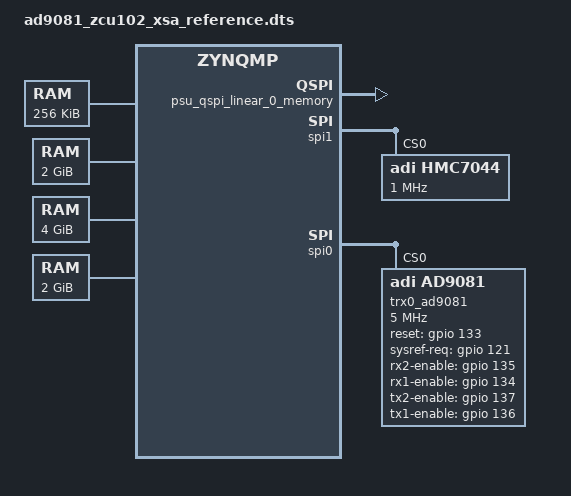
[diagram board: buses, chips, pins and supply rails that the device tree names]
/*
 * ADI Device Tree (merged) — ad9081_zcu102
 *
 * Generated by pyadi-dt from XSA. Do not edit manually — re-run
 * the pipeline to regenerate from the XSA source.
 *
 * Compile with:
 *   dtc -I dts -O dtb -o system.dtb ad9081_zcu102.dts
 */
/dts-v1/;
#include "zynqmp.dtsi"
#include "zynqmp-u-boot.dtsi"
#include "zynqmp-clk-ccf.dtsi"
#include "pl.dtsi"
#include "pcw.dtsi"
/ {
	board = "zcu102";
	compatible = "xlnx,zcu102";
	device_id = "xczu9eg";
	slrcount = <1>;
	family = "ZynqMP";
	speed_grade = "2";
	psu_ocm_ram_0_memory: memory@FFFC0000 {
		compatible = "xlnx,psu-ocm-ram-0-1.0" , "mmio-sram";
		xlnx,ip-name = "psu_ocm_ram_0";
		memory_type = "memory";
		reg = <0x0 0xFFFC0000 0x0 0x40000>;
	};
	psu_r5_ddr_0_memory: memory@100000 {
		compatible = "xlnx,psu-ddr-1.0";
		xlnx,ip-name = "psu_ddr";
		device_type = "memory";
		memory_type = "memory";
		reg = <0x100000 0x7FEFFFFF>;
	};
	psu_ddr_0_memory: memory@0 {
		compatible = "xlnx,psu-ddr-1.0";
		xlnx,ip-name = "psu_ddr";
		device_type = "memory";
		memory_type = "memory";
		reg = <0x0 0x7FF00000>, <0x0 0x7FF00000 0x0 0x100000>;
	};
	psu_ddr_1_memory: memory@800000000 {
		compatible = "xlnx,psu-ddr-1.0";
		xlnx,ip-name = "psu_ddr";
		device_type = "memory";
		memory_type = "memory";
		reg = <0x00000008 0x00000000 0x0 0x80000000>;
	};
	psu_qspi_linear_0_memory: memory@c0000000 {
		compatible = "xlnx,psu-qspi-linear-1.0-memory";
		xlnx,ip-name = "psu_qspi_linear";
		memory_type = "linear_flash";
		reg = <0x0 0xc0000000 0x0 0x20000000>;
	};
	chosen {
		bootargs = "earlycon console=ttyPS0,115200 clk_ignore_unused init_fatal_sh=1";
		stdout-path = "serial0:115200n8";
	};
	aliases {
		serial0 = &uart0;
		spi0 = &qspi;
		serial1 = &uart1;
		serial2 = &coresight_0;
		i2c0 = &i2c1;
		i2c1 = &i2c0;
		ethernet0 = &gem3;
	};
	cpus_a53: cpus {
		compatible = "cpus,cluster";
		address-map = <0x0 0xf0000000 &amba 0x0 0xf0000000 0x0 0x10000000>, 
			      <0x0 0xf9000000 &amba_apu 0x0 0xf9000000 0x0 0x80000>, 
			      <0x0 0x0 &zynqmp_reset 0x0 0x0 0x0 0x0>, 
			      <0x0 0x0 &pinctrl0 0x0 0x0 0x0 0x0>, 
			      <0x0 0xffa50800 &ams_ps 0x0 0xffa50800 0x0 0x400>, 
			      <0x0 0xffa50c00 &ams_pl 0x0 0xffa50c00 0x0 0x400>, 
			      <0x0 0xFFFC0000 &psu_ocm_ram_0_memory 0x0 0xFFFC0000 0x0 0x40000>, 
			      <0x0 0xff300000 &ipi0 0x0 0xff300000 0x0 0x10000>, 
			      <0x0 0x0 &psu_ddr_0_memory 0x0 0x0 0x0 0x7FF00000>, 
			      <0x00000008 0x00000000 &psu_ddr_1_memory 0x00000008 0x00000000 0x0 0x80000000>, 
			      <0x0 0x84a10000 &rx_mxfe_tpl_core_adc_tpl_core 0x0 0x84a10000 0x0 0x2000>, 
			      <0x0 0x84a60000 &axi_mxfe_rx_xcvr 0x0 0x84a60000 0x0 0x10000>, 
			      <0x0 0x84a90000 &axi_mxfe_rx_jesd_rx_axi 0x0 0x84a90000 0x0 0x4000>, 
			      <0x0 0x84b10000 &tx_mxfe_tpl_core_dac_tpl_core 0x0 0x84b10000 0x0 0x2000>, 
			      <0x0 0x84b60000 &axi_mxfe_tx_xcvr 0x0 0x84b60000 0x0 0x10000>, 
			      <0x0 0x84b90000 &axi_mxfe_tx_jesd_tx_axi 0x0 0x84b90000 0x0 0x4000>, 
			      <0x0 0x85000000 &axi_sysid_0 0x0 0x85000000 0x0 0x10000>, 
			      <0x0 0x9c420000 &axi_mxfe_rx_dma 0x0 0x9c420000 0x0 0x1000>, 
			      <0x0 0x9c430000 &axi_mxfe_tx_dma 0x0 0x9c430000 0x0 0x1000>, 
			      <0x0 0x9c440000 &mxfe_tx_data_offload_i_data_offload 0x0 0x9c440000 0x0 0x10000>, 
			      <0x0 0x9c450000 &mxfe_rx_data_offload_i_data_offload 0x0 0x9c450000 0x0 0x10000>, 
			      <0x0 0xf9010000 &gic_a53 0x0 0xf9010000 0x0 0x70000>, 
			      <0x0 0xffa80000 &lpd_dma_chan1 0x0 0xffa80000 0x0 0x10000>, 
			      <0x0 0xffa90000 &lpd_dma_chan2 0x0 0xffa90000 0x0 0x10000>, 
			      <0x0 0xffaa0000 &lpd_dma_chan3 0x0 0xffaa0000 0x0 0x10000>, 
			      <0x0 0xffab0000 &lpd_dma_chan4 0x0 0xffab0000 0x0 0x10000>, 
			      <0x0 0xffac0000 &lpd_dma_chan5 0x0 0xffac0000 0x0 0x10000>, 
			      <0x0 0xffad0000 &lpd_dma_chan6 0x0 0xffad0000 0x0 0x10000>, 
			      <0x0 0xffae0000 &lpd_dma_chan7 0x0 0xffae0000 0x0 0x10000>, 
			      <0x0 0xffaf0000 &lpd_dma_chan8 0x0 0xffaf0000 0x0 0x10000>, 
			      <0x0 0xfd360000 &psu_afi_0 0x0 0xfd360000 0x0 0x10000>, 
			      <0x0 0xfd370000 &psu_afi_1 0x0 0xfd370000 0x0 0x10000>, 
			      <0x0 0xfd380000 &psu_afi_2 0x0 0xfd380000 0x0 0x10000>, 
			      <0x0 0xfd390000 &psu_afi_3 0x0 0xfd390000 0x0 0x10000>, 
			      <0x0 0xfd3a0000 &psu_afi_4 0x0 0xfd3a0000 0x0 0x10000>, 
			      <0x0 0xfd3b0000 &psu_afi_5 0x0 0xfd3b0000 0x0 0x10000>, 
			      <0x0 0xff9b0000 &psu_afi_6 0x0 0xff9b0000 0x0 0x10000>, 
			      <0x0 0xffa50000 &xilinx_ams 0x0 0xffa50000 0x0 0x10000>, 
			      <0x0 0xfd0b0000 &perf_monitor_ddr 0x0 0xfd0b0000 0x0 0x10000>, 
			      <0x0 0xffa00000 &perf_monitor_ocm 0x0 0xffa00000 0x0 0x10000>, 
			      <0x0 0xffa10000 &perf_monitor_lpd 0x0 0xffa10000 0x0 0x10000>, 
			      <0x0 0xfd490000 &perf_monitor_cci 0x0 0xfd490000 0x0 0x10000>, 
			      <0x0 0xfd5c0000 &psu_apu 0x0 0xfd5c0000 0x0 0x10000>, 
			      <0x0 0xff070000 &can1 0x0 0xff070000 0x0 0x10000>, 
			      <0x0 0xfd6e0000 &psu_cci_gpv 0x0 0xfd6e0000 0x0 0x10000>, 
			      <0x0 0xfd5e0000 &psu_cci_reg 0x0 0xfd5e0000 0x0 0x10000>, 
			      <0x0 0xfe800000 &coresight_0 0x0 0xfe800000 0x0 0x800000>, 
			      <0x0 0xfd1a0000 &psu_crf_apb 0x0 0xfd1a0000 0x0 0x140000>, 
			      <0x0 0xff5e0000 &psu_crl_apb 0x0 0xff5e0000 0x0 0x280000>, 
			      <0x0 0xffca0000 &psu_csu_0 0x0 0xffca0000 0x0 0x10000>, 
			      <0x0 0xffc80000 &csudma_0 0x0 0xffc80000 0x0 0x20000>, 
			      <0x0 0xff380000 &psu_ctrl_ipi 0x0 0xff380000 0x0 0x80000>, 
			      <0x0 0xfd080000 &psu_ddr_phy 0x0 0xfd080000 0x0 0x10000>, 
			      <0x0 0xfd090000 &psu_ddr_qos_ctrl 0x0 0xfd090000 0x0 0x10000>, 
			      <0x0 0xfd000000 &psu_ddr_xmpu0_cfg 0x0 0xfd000000 0x0 0x10000>, 
			      <0x0 0xfd010000 &psu_ddr_xmpu1_cfg 0x0 0xfd010000 0x0 0x10000>, 
			      <0x0 0xfd020000 &psu_ddr_xmpu2_cfg 0x0 0xfd020000 0x0 0x10000>, 
			      <0x0 0xfd030000 &psu_ddr_xmpu3_cfg 0x0 0xfd030000 0x0 0x10000>, 
			      <0x0 0xfd040000 &psu_ddr_xmpu4_cfg 0x0 0xfd040000 0x0 0x10000>, 
			      <0x0 0xfd050000 &psu_ddr_xmpu5_cfg 0x0 0xfd050000 0x0 0x10000>, 
			      <0x0 0xfd070000 &mc 0x0 0xfd070000 0x0 0x1000>, 
			      <0x0 0xfd4a0000 &zynqmp_dpsub 0x0 0xfd4a0000 0x0 0x10000>, 
			      <0x0 0xfd4c0000 &zynqmp_dpdma 0x0 0xfd4c0000 0x0 0x10000>, 
			      <0x0 0xffcc0000 &psu_efuse 0x0 0xffcc0000 0x0 0x10000>, 
			      <0x0 0xff0e0000 &gem3 0x0 0xff0e0000 0x0 0x10000>, 
			      <0x0 0xfd700000 &psu_fpd_gpv 0x0 0xfd700000 0x0 0x100000>, 
			      <0x0 0xfd610000 &psu_fpd_slcr 0x0 0xfd610000 0x0 0x80000>, 
			      <0x0 0xfd690000 &psu_fpd_slcr_secure 0x0 0xfd690000 0x0 0x40000>, 
			      <0x0 0xfd5d0000 &psu_fpd_xmpu_cfg 0x0 0xfd5d0000 0x0 0x10000>, 
			      <0x0 0xfd4f0000 &psu_fpd_xmpu_sink 0x0 0xfd4f0000 0x0 0x10000>, 
			      <0x0 0xfd500000 &fpd_dma_chan1 0x0 0xfd500000 0x0 0x10000>, 
			      <0x0 0xfd510000 &fpd_dma_chan2 0x0 0xfd510000 0x0 0x10000>, 
			      <0x0 0xfd520000 &fpd_dma_chan3 0x0 0xfd520000 0x0 0x10000>, 
			      <0x0 0xfd530000 &fpd_dma_chan4 0x0 0xfd530000 0x0 0x10000>, 
			      <0x0 0xfd540000 &fpd_dma_chan5 0x0 0xfd540000 0x0 0x10000>, 
			      <0x0 0xfd550000 &fpd_dma_chan6 0x0 0xfd550000 0x0 0x10000>, 
			      <0x0 0xfd560000 &fpd_dma_chan7 0x0 0xfd560000 0x0 0x10000>, 
			      <0x0 0xfd570000 &fpd_dma_chan8 0x0 0xfd570000 0x0 0x10000>, 
			      <0x0 0xff0a0000 &gpio 0x0 0xff0a0000 0x0 0x10000>, 
			      <0x0 0xfd4b0000 &gpu 0x0 0xfd4b0000 0x0 0x10000>, 
			      <0x0 0xff020000 &i2c0 0x0 0xff020000 0x0 0x10000>, 
			      <0x0 0xff030000 &i2c1 0x0 0xff030000 0x0 0x10000>, 
			      <0x0 0xff250000 &psu_iou_scntr 0x0 0xff250000 0x0 0x10000>, 
			      <0x0 0xff260000 &psu_iou_scntrs 0x0 0xff260000 0x0 0x10000>, 
			      <0x0 0xff240000 &psu_iousecure_slcr 0x0 0xff240000 0x0 0x10000>, 
			      <0x0 0xff180000 &psu_iouslcr_0 0x0 0xff180000 0x0 0xc0000>, 
			      <0x0 0xff410000 &psu_lpd_slcr 0x0 0xff410000 0x0 0xa0000>, 
			      <0x0 0xff4b0000 &psu_lpd_slcr_secure 0x0 0xff4b0000 0x0 0x30000>, 
			      <0x0 0xff980000 &lpd_xppu 0x0 0xff980000 0x0 0x10000>, 
			      <0x0 0xff9c0000 &psu_lpd_xppu_sink 0x0 0xff9c0000 0x0 0x10000>, 
			      <0x0 0xffcf0000 &psu_mbistjtag 0x0 0xffcf0000 0x0 0x10000>, 
			      <0x0 0xff990000 &psu_message_buffers 0x0 0xff990000 0x0 0x10000>, 
			      <0x0 0xff960000 &ocm 0x0 0xff960000 0x0 0x10000>, 
			      <0x0 0xffa70000 &psu_ocm_xmpu_cfg 0x0 0xffa70000 0x0 0x10000>, 
			      <0x0 0xfd0e0000 &pcie 0x0 0xfd0e0000 0x0 0x10000>, 
			      <0x0 0xfd480000 &psu_pcie_attrib_0 0x0 0xfd480000 0x0 0x10000>, 
			      <0x0 0xfd0f0000 &psu_pcie_dma 0x0 0xfd0f0000 0x0 0x10000>, 
			      <0x00000006 0x00000000 &psu_pcie_high1 0x00000006 0x00000000 0x00000002 0x00000000>, 
			      <0x00000080 0x00000000 &psu_pcie_high2 0x00000080 0x00000000 0x00000040 0x00000000>, 
			      <0x0 0xe0000000 &psu_pcie_low 0x0 0xe0000000 0x0 0x10000000>, 
			      <0x0 0xffd80000 &psu_pmu_global_0 0x0 0xffd80000 0x0 0x40000>, 
			      <0x0 0xff0f0000 &qspi 0x0 0xff0f0000 0x0 0x10000>, 
			      <0x0 0xc0000000 &psu_qspi_linear_0_memory 0x0 0xc0000000 0x0 0x20000000>, 
			      <0x0 0xffe00000 &psu_r5_0_atcm_global 0x0 0xffe00000 0x0 0x10000>, 
			      <0x0 0xffe20000 &psu_r5_0_btcm_global 0x0 0xffe20000 0x0 0x10000>, 
			      <0x0 0xffe90000 &psu_r5_1_atcm_global 0x0 0xffe90000 0x0 0x10000>, 
			      <0x0 0xffeb0000 &psu_r5_1_btcm_global 0x0 0xffeb0000 0x0 0x10000>, 
			      <0x0 0xffe00000 &psu_r5_tcm_ram_global 0x0 0xffe00000 0x0 0x40000>, 
			      <0x0 0xff9a0000 &psu_rpu 0x0 0xff9a0000 0x0 0x10000>, 
			      <0x0 0xffce0000 &psu_rsa 0x0 0xffce0000 0x0 0x10000>, 
			      <0x0 0xffa60000 &rtc 0x0 0xffa60000 0x0 0x10000>, 
			      <0x0 0xfd0c0000 &sata 0x0 0xfd0c0000 0x0 0x10000>, 
			      <0x0 0xff170000 &sdhci1 0x0 0xff170000 0x0 0x10000>, 
			      <0x0 0xfd400000 &psgtr 0x0 0xfd400000 0x0 0x80000>, 
			      <0x0 0xfd3d0000 &psu_siou 0x0 0xfd3d0000 0x0 0x10000>, 
			      <0x0 0xfd800000 &smmu 0x0 0xfd800000 0x0 0x800000>, 
			      <0x0 0xfd5f0000 &psu_smmu_reg 0x0 0xfd5f0000 0x0 0x10000>, 
			      <0x0 0xff040000 &spi0 0x0 0xff040000 0x0 0x10000>, 
			      <0x0 0xff050000 &spi1 0x0 0xff050000 0x0 0x10000>, 
			      <0x0 0xff110000 &ttc0 0x0 0xff110000 0x0 0x10000>, 
			      <0x0 0xff120000 &ttc1 0x0 0xff120000 0x0 0x10000>, 
			      <0x0 0xff130000 &ttc2 0x0 0xff130000 0x0 0x10000>, 
			      <0x0 0xff140000 &ttc3 0x0 0xff140000 0x0 0x10000>, 
			      <0x0 0xff000000 &uart0 0x0 0xff000000 0x0 0x10000>, 
			      <0x0 0xff010000 &uart1 0x0 0xff010000 0x0 0x10000>, 
			      <0x0 0xff9d0000 &usb0 0x0 0xff9d0000 0x0 0x10000>, 
			      <0x0 0xfe200000 &dwc3_0 0x0 0xfe200000 0x0 0x100000>, 
			      <0x0 0xff150000 &lpd_watchdog 0x0 0xff150000 0x0 0x10000>, 
			      <0x0 0xfd4d0000 &watchdog0 0x0 0xfd4d0000 0x0 0x10000>;
		#ranges-address-cells = <0x2>;
		#ranges-size-cells = <0x2>;
	};
	cpus_r5_0: cpus-r5@0 {
		compatible = "cpus,cluster";
		address-map = <0xf0000000 &amba 0xf0000000 0x10000000>, 
			      <0xf9000000 &amba_rpu 0xf9000000 0x3000>, 
			      <0x0 &zynqmp_reset 0x0 0x0>, 
			      <0xFFFC0000 &psu_ocm_ram_0_memory 0xFFFC0000 0x40000>, 
			      <0xff310000 &ipi1 0xff310000 0x10000>, 
			      <0x100000 &psu_r5_ddr_0_memory 0x100000 0x7FEFFFFF>, 
			      <0x84a10000 &rx_mxfe_tpl_core_adc_tpl_core 0x84a10000 0x2000>, 
			      <0x84a60000 &axi_mxfe_rx_xcvr 0x84a60000 0x10000>, 
			      <0x84a90000 &axi_mxfe_rx_jesd_rx_axi 0x84a90000 0x4000>, 
			      <0x84b10000 &tx_mxfe_tpl_core_dac_tpl_core 0x84b10000 0x2000>, 
			      <0x84b60000 &axi_mxfe_tx_xcvr 0x84b60000 0x10000>, 
			      <0x84b90000 &axi_mxfe_tx_jesd_tx_axi 0x84b90000 0x4000>, 
			      <0x85000000 &axi_sysid_0 0x85000000 0x10000>, 
			      <0x9c420000 &axi_mxfe_rx_dma 0x9c420000 0x1000>, 
			      <0x9c430000 &axi_mxfe_tx_dma 0x9c430000 0x1000>, 
			      <0x9c440000 &mxfe_tx_data_offload_i_data_offload 0x9c440000 0x10000>, 
			      <0x9c450000 &mxfe_rx_data_offload_i_data_offload 0x9c450000 0x10000>, 
			      <0xffa80000 &lpd_dma_chan1 0xffa80000 0x10000>, 
			      <0xffa90000 &lpd_dma_chan2 0xffa90000 0x10000>, 
			      <0xffaa0000 &lpd_dma_chan3 0xffaa0000 0x10000>, 
			      <0xffab0000 &lpd_dma_chan4 0xffab0000 0x10000>, 
			      <0xffac0000 &lpd_dma_chan5 0xffac0000 0x10000>, 
			      <0xffad0000 &lpd_dma_chan6 0xffad0000 0x10000>, 
			      <0xffae0000 &lpd_dma_chan7 0xffae0000 0x10000>, 
			      <0xffaf0000 &lpd_dma_chan8 0xffaf0000 0x10000>, 
			      <0xfd360000 &psu_afi_0 0xfd360000 0x10000>, 
			      <0xfd370000 &psu_afi_1 0xfd370000 0x10000>, 
			      <0xfd380000 &psu_afi_2 0xfd380000 0x10000>, 
			      <0xfd390000 &psu_afi_3 0xfd390000 0x10000>, 
			      <0xfd3a0000 &psu_afi_4 0xfd3a0000 0x10000>, 
			      <0xfd3b0000 &psu_afi_5 0xfd3b0000 0x10000>, 
			      <0xff9b0000 &psu_afi_6 0xff9b0000 0x10000>, 
			      <0xffa50000 &xilinx_ams 0xffa50000 0x10000>, 
			      <0xfd0b0000 &perf_monitor_ddr 0xfd0b0000 0x10000>, 
			      <0xffa00000 &perf_monitor_ocm 0xffa00000 0x10000>, 
			      <0xffa10000 &perf_monitor_lpd 0xffa10000 0x10000>, 
			      <0xfd490000 &perf_monitor_cci 0xfd490000 0x10000>, 
			      <0xfd5c0000 &psu_apu 0xfd5c0000 0x10000>, 
			      <0xff070000 &can1 0xff070000 0x10000>, 
			      <0xfd6e0000 &psu_cci_gpv 0xfd6e0000 0x10000>, 
			      <0xfd5e0000 &psu_cci_reg 0xfd5e0000 0x10000>, 
			      <0xfe800000 &coresight_0 0xfe800000 0x800000>, 
			      <0xfd1a0000 &psu_crf_apb 0xfd1a0000 0x140000>, 
			      <0xff5e0000 &psu_crl_apb 0xff5e0000 0x280000>, 
			      <0xffca0000 &psu_csu_0 0xffca0000 0x10000>, 
			      <0xffc80000 &csudma_0 0xffc80000 0x20000>, 
			      <0xff380000 &psu_ctrl_ipi 0xff380000 0x80000>, 
			      <0xfd080000 &psu_ddr_phy 0xfd080000 0x10000>, 
			      <0xfd090000 &psu_ddr_qos_ctrl 0xfd090000 0x10000>, 
			      <0xfd000000 &psu_ddr_xmpu0_cfg 0xfd000000 0x10000>, 
			      <0xfd010000 &psu_ddr_xmpu1_cfg 0xfd010000 0x10000>, 
			      <0xfd020000 &psu_ddr_xmpu2_cfg 0xfd020000 0x10000>, 
			      <0xfd030000 &psu_ddr_xmpu3_cfg 0xfd030000 0x10000>, 
			      <0xfd040000 &psu_ddr_xmpu4_cfg 0xfd040000 0x10000>, 
			      <0xfd050000 &psu_ddr_xmpu5_cfg 0xfd050000 0x10000>, 
			      <0xfd070000 &mc 0xfd070000 0x1000>, 
			      <0xfd4a0000 &zynqmp_dpsub 0xfd4a0000 0x10000>, 
			      <0xfd4c0000 &zynqmp_dpdma 0xfd4c0000 0x10000>, 
			      <0xffcc0000 &psu_efuse 0xffcc0000 0x10000>, 
			      <0xff0e0000 &gem3 0xff0e0000 0x10000>, 
			      <0xfd700000 &psu_fpd_gpv 0xfd700000 0x100000>, 
			      <0xfd610000 &psu_fpd_slcr 0xfd610000 0x80000>, 
			      <0xfd690000 &psu_fpd_slcr_secure 0xfd690000 0x40000>, 
			      <0xfd5d0000 &psu_fpd_xmpu_cfg 0xfd5d0000 0x10000>, 
			      <0xfd4f0000 &psu_fpd_xmpu_sink 0xfd4f0000 0x10000>, 
			      <0xfd500000 &fpd_dma_chan1 0xfd500000 0x10000>, 
			      <0xfd510000 &fpd_dma_chan2 0xfd510000 0x10000>, 
			      <0xfd520000 &fpd_dma_chan3 0xfd520000 0x10000>, 
			      <0xfd530000 &fpd_dma_chan4 0xfd530000 0x10000>, 
			      <0xfd540000 &fpd_dma_chan5 0xfd540000 0x10000>, 
			      <0xfd550000 &fpd_dma_chan6 0xfd550000 0x10000>, 
			      <0xfd560000 &fpd_dma_chan7 0xfd560000 0x10000>, 
			      <0xfd570000 &fpd_dma_chan8 0xfd570000 0x10000>, 
			      <0xff0a0000 &gpio 0xff0a0000 0x10000>, 
			      <0xfd4b0000 &gpu 0xfd4b0000 0x10000>, 
			      <0xff020000 &i2c0 0xff020000 0x10000>, 
			      <0xff030000 &i2c1 0xff030000 0x10000>, 
			      <0xff250000 &psu_iou_scntr 0xff250000 0x10000>, 
			      <0xff260000 &psu_iou_scntrs 0xff260000 0x10000>, 
			      <0xff240000 &psu_iousecure_slcr 0xff240000 0x10000>, 
			      <0xff180000 &psu_iouslcr_0 0xff180000 0xc0000>, 
			      <0xff410000 &psu_lpd_slcr 0xff410000 0xa0000>, 
			      <0xff4b0000 &psu_lpd_slcr_secure 0xff4b0000 0x30000>, 
			      <0xff980000 &lpd_xppu 0xff980000 0x10000>, 
			      <0xff9c0000 &psu_lpd_xppu_sink 0xff9c0000 0x10000>, 
			      <0xffcf0000 &psu_mbistjtag 0xffcf0000 0x10000>, 
			      <0xff990000 &psu_message_buffers 0xff990000 0x10000>, 
			      <0xff960000 &ocm 0xff960000 0x10000>, 
			      <0xffa70000 &psu_ocm_xmpu_cfg 0xffa70000 0x10000>, 
			      <0xfd0e0000 &pcie 0xfd0e0000 0x10000>, 
			      <0xfd480000 &psu_pcie_attrib_0 0xfd480000 0x10000>, 
			      <0xfd0f0000 &psu_pcie_dma 0xfd0f0000 0x10000>, 
			      <0xe0000000 &psu_pcie_low 0xe0000000 0x10000000>, 
			      <0xffd80000 &psu_pmu_global_0 0xffd80000 0x40000>, 
			      <0xff0f0000 &qspi 0xff0f0000 0x10000>, 
			      <0xc0000000 &psu_qspi_linear_0_memory 0xc0000000 0x20000000>, 
			      <0xff9a0000 &psu_rpu 0xff9a0000 0x10000>, 
			      <0xffce0000 &psu_rsa 0xffce0000 0x10000>, 
			      <0xffa60000 &rtc 0xffa60000 0x10000>, 
			      <0xfd0c0000 &sata 0xfd0c0000 0x10000>, 
			      <0xff170000 &sdhci1 0xff170000 0x10000>, 
			      <0xfd400000 &psgtr 0xfd400000 0x80000>, 
			      <0xfd3d0000 &psu_siou 0xfd3d0000 0x10000>, 
			      <0xfd800000 &smmu 0xfd800000 0x800000>, 
			      <0xfd5f0000 &psu_smmu_reg 0xfd5f0000 0x10000>, 
			      <0xff040000 &spi0 0xff040000 0x10000>, 
			      <0xff050000 &spi1 0xff050000 0x10000>, 
			      <0xff110000 &ttc0 0xff110000 0x10000>, 
			      <0xff120000 &ttc1 0xff120000 0x10000>, 
			      <0xff130000 &ttc2 0xff130000 0x10000>, 
			      <0xff140000 &ttc3 0xff140000 0x10000>, 
			      <0xff000000 &uart0 0xff000000 0x10000>, 
			      <0xff010000 &uart1 0xff010000 0x10000>, 
			      <0xff9d0000 &usb0 0xff9d0000 0x10000>, 
			      <0xfe200000 &dwc3_0 0xfe200000 0x100000>, 
			      <0xff150000 &lpd_watchdog 0xff150000 0x10000>, 
			      <0xfd4d0000 &watchdog0 0xfd4d0000 0x10000>, 
			      <0xffcb0000 &csuwdt_0 0xffcb0000 0x10000>, 
			      <0x0 &psu_r5_0_atcm 0x0 0x10000>, 
			      <0x20000 &psu_r5_0_btcm 0x20000 0x10000>, 
			      <0x0 &psu_r5_tcm_ram_0 0x0 0x40000>, 
			      <0xf9000000 &gic_r5 0xf9000000 0x10000>;
		#ranges-address-cells = <0x1>;
		#ranges-size-cells = <0x1>;
	};
	cpus_r5_1: cpus-r5@1 {
		compatible = "cpus,cluster";
		address-map = <0xf0000000 &amba 0xf0000000 0x10000000>, 
			      <0xf9000000 &amba_rpu 0xf9000000 0x3000>, 
			      <0x0 &zynqmp_reset 0x0 0x0>, 
			      <0xFFFC0000 &psu_ocm_ram_0_memory 0xFFFC0000 0x40000>, 
			      <0xff320000 &ipi2 0xff320000 0x10000>, 
			      <0x100000 &psu_r5_ddr_0_memory 0x100000 0x7FEFFFFF>, 
			      <0x84a10000 &rx_mxfe_tpl_core_adc_tpl_core 0x84a10000 0x2000>, 
			      <0x84a60000 &axi_mxfe_rx_xcvr 0x84a60000 0x10000>, 
			      <0x84a90000 &axi_mxfe_rx_jesd_rx_axi 0x84a90000 0x4000>, 
			      <0x84b10000 &tx_mxfe_tpl_core_dac_tpl_core 0x84b10000 0x2000>, 
			      <0x84b60000 &axi_mxfe_tx_xcvr 0x84b60000 0x10000>, 
			      <0x84b90000 &axi_mxfe_tx_jesd_tx_axi 0x84b90000 0x4000>, 
			      <0x85000000 &axi_sysid_0 0x85000000 0x10000>, 
			      <0x9c420000 &axi_mxfe_rx_dma 0x9c420000 0x1000>, 
			      <0x9c430000 &axi_mxfe_tx_dma 0x9c430000 0x1000>, 
			      <0x9c440000 &mxfe_tx_data_offload_i_data_offload 0x9c440000 0x10000>, 
			      <0x9c450000 &mxfe_rx_data_offload_i_data_offload 0x9c450000 0x10000>, 
			      <0xffa80000 &lpd_dma_chan1 0xffa80000 0x10000>, 
			      <0xffa90000 &lpd_dma_chan2 0xffa90000 0x10000>, 
			      <0xffaa0000 &lpd_dma_chan3 0xffaa0000 0x10000>, 
			      <0xffab0000 &lpd_dma_chan4 0xffab0000 0x10000>, 
			      <0xffac0000 &lpd_dma_chan5 0xffac0000 0x10000>, 
			      <0xffad0000 &lpd_dma_chan6 0xffad0000 0x10000>, 
			      <0xffae0000 &lpd_dma_chan7 0xffae0000 0x10000>, 
			      <0xffaf0000 &lpd_dma_chan8 0xffaf0000 0x10000>, 
			      <0xfd360000 &psu_afi_0 0xfd360000 0x10000>, 
			      <0xfd370000 &psu_afi_1 0xfd370000 0x10000>, 
			      <0xfd380000 &psu_afi_2 0xfd380000 0x10000>, 
			      <0xfd390000 &psu_afi_3 0xfd390000 0x10000>, 
			      <0xfd3a0000 &psu_afi_4 0xfd3a0000 0x10000>, 
			      <0xfd3b0000 &psu_afi_5 0xfd3b0000 0x10000>, 
			      <0xff9b0000 &psu_afi_6 0xff9b0000 0x10000>, 
			      <0xffa50000 &xilinx_ams 0xffa50000 0x10000>, 
			      <0xfd0b0000 &perf_monitor_ddr 0xfd0b0000 0x10000>, 
			      <0xffa00000 &perf_monitor_ocm 0xffa00000 0x10000>, 
			      <0xffa10000 &perf_monitor_lpd 0xffa10000 0x10000>, 
			      <0xfd490000 &perf_monitor_cci 0xfd490000 0x10000>, 
			      <0xfd5c0000 &psu_apu 0xfd5c0000 0x10000>, 
			      <0xff070000 &can1 0xff070000 0x10000>, 
			      <0xfd6e0000 &psu_cci_gpv 0xfd6e0000 0x10000>, 
			      <0xfd5e0000 &psu_cci_reg 0xfd5e0000 0x10000>, 
			      <0xfe800000 &coresight_0 0xfe800000 0x800000>, 
			      <0xfd1a0000 &psu_crf_apb 0xfd1a0000 0x140000>, 
			      <0xff5e0000 &psu_crl_apb 0xff5e0000 0x280000>, 
			      <0xffca0000 &psu_csu_0 0xffca0000 0x10000>, 
			      <0xffc80000 &csudma_0 0xffc80000 0x20000>, 
			      <0xff380000 &psu_ctrl_ipi 0xff380000 0x80000>, 
			      <0xfd080000 &psu_ddr_phy 0xfd080000 0x10000>, 
			      <0xfd090000 &psu_ddr_qos_ctrl 0xfd090000 0x10000>, 
			      <0xfd000000 &psu_ddr_xmpu0_cfg 0xfd000000 0x10000>, 
			      <0xfd010000 &psu_ddr_xmpu1_cfg 0xfd010000 0x10000>, 
			      <0xfd020000 &psu_ddr_xmpu2_cfg 0xfd020000 0x10000>, 
			      <0xfd030000 &psu_ddr_xmpu3_cfg 0xfd030000 0x10000>, 
			      <0xfd040000 &psu_ddr_xmpu4_cfg 0xfd040000 0x10000>, 
			      <0xfd050000 &psu_ddr_xmpu5_cfg 0xfd050000 0x10000>, 
			      <0xfd070000 &mc 0xfd070000 0x1000>, 
			      <0xfd4a0000 &zynqmp_dpsub 0xfd4a0000 0x10000>, 
			      <0xfd4c0000 &zynqmp_dpdma 0xfd4c0000 0x10000>, 
			      <0xffcc0000 &psu_efuse 0xffcc0000 0x10000>, 
			      <0xff0e0000 &gem3 0xff0e0000 0x10000>, 
			      <0xfd700000 &psu_fpd_gpv 0xfd700000 0x100000>, 
			      <0xfd610000 &psu_fpd_slcr 0xfd610000 0x80000>, 
			      <0xfd690000 &psu_fpd_slcr_secure 0xfd690000 0x40000>, 
			      <0xfd5d0000 &psu_fpd_xmpu_cfg 0xfd5d0000 0x10000>, 
			      <0xfd4f0000 &psu_fpd_xmpu_sink 0xfd4f0000 0x10000>, 
			      <0xfd500000 &fpd_dma_chan1 0xfd500000 0x10000>, 
			      <0xfd510000 &fpd_dma_chan2 0xfd510000 0x10000>, 
			      <0xfd520000 &fpd_dma_chan3 0xfd520000 0x10000>, 
			      <0xfd530000 &fpd_dma_chan4 0xfd530000 0x10000>, 
			      <0xfd540000 &fpd_dma_chan5 0xfd540000 0x10000>, 
			      <0xfd550000 &fpd_dma_chan6 0xfd550000 0x10000>, 
			      <0xfd560000 &fpd_dma_chan7 0xfd560000 0x10000>, 
			      <0xfd570000 &fpd_dma_chan8 0xfd570000 0x10000>, 
			      <0xff0a0000 &gpio 0xff0a0000 0x10000>, 
			      <0xfd4b0000 &gpu 0xfd4b0000 0x10000>, 
			      <0xff020000 &i2c0 0xff020000 0x10000>, 
			      <0xff030000 &i2c1 0xff030000 0x10000>, 
			      <0xff250000 &psu_iou_scntr 0xff250000 0x10000>, 
			      <0xff260000 &psu_iou_scntrs 0xff260000 0x10000>, 
			      <0xff240000 &psu_iousecure_slcr 0xff240000 0x10000>, 
			      <0xff180000 &psu_iouslcr_0 0xff180000 0xc0000>, 
			      <0xff410000 &psu_lpd_slcr 0xff410000 0xa0000>, 
			      <0xff4b0000 &psu_lpd_slcr_secure 0xff4b0000 0x30000>, 
			      <0xff980000 &lpd_xppu 0xff980000 0x10000>, 
			      <0xff9c0000 &psu_lpd_xppu_sink 0xff9c0000 0x10000>, 
			      <0xffcf0000 &psu_mbistjtag 0xffcf0000 0x10000>, 
			      <0xff990000 &psu_message_buffers 0xff990000 0x10000>, 
			      <0xff960000 &ocm 0xff960000 0x10000>, 
			      <0xffa70000 &psu_ocm_xmpu_cfg 0xffa70000 0x10000>, 
			      <0xfd0e0000 &pcie 0xfd0e0000 0x10000>, 
			      <0xfd480000 &psu_pcie_attrib_0 0xfd480000 0x10000>, 
			      <0xfd0f0000 &psu_pcie_dma 0xfd0f0000 0x10000>, 
			      <0xe0000000 &psu_pcie_low 0xe0000000 0x10000000>, 
			      <0xffd80000 &psu_pmu_global_0 0xffd80000 0x40000>, 
			      <0xff0f0000 &qspi 0xff0f0000 0x10000>, 
			      <0xc0000000 &psu_qspi_linear_0_memory 0xc0000000 0x20000000>, 
			      <0xff9a0000 &psu_rpu 0xff9a0000 0x10000>, 
			      <0xffce0000 &psu_rsa 0xffce0000 0x10000>, 
			      <0xffa60000 &rtc 0xffa60000 0x10000>, 
			      <0xfd0c0000 &sata 0xfd0c0000 0x10000>, 
			      <0xff170000 &sdhci1 0xff170000 0x10000>, 
			      <0xfd400000 &psgtr 0xfd400000 0x80000>, 
			      <0xfd3d0000 &psu_siou 0xfd3d0000 0x10000>, 
			      <0xfd800000 &smmu 0xfd800000 0x800000>, 
			      <0xfd5f0000 &psu_smmu_reg 0xfd5f0000 0x10000>, 
			      <0xff040000 &spi0 0xff040000 0x10000>, 
			      <0xff050000 &spi1 0xff050000 0x10000>, 
			      <0xff110000 &ttc0 0xff110000 0x10000>, 
			      <0xff120000 &ttc1 0xff120000 0x10000>, 
			      <0xff130000 &ttc2 0xff130000 0x10000>, 
			      <0xff140000 &ttc3 0xff140000 0x10000>, 
			      <0xff000000 &uart0 0xff000000 0x10000>, 
			      <0xff010000 &uart1 0xff010000 0x10000>, 
			      <0xff9d0000 &usb0 0xff9d0000 0x10000>, 
			      <0xfe200000 &dwc3_0 0xfe200000 0x100000>, 
			      <0xff150000 &lpd_watchdog 0xff150000 0x10000>, 
			      <0xfd4d0000 &watchdog0 0xfd4d0000 0x10000>, 
			      <0xffcb0000 &csuwdt_0 0xffcb0000 0x10000>, 
			      <0xf9000000 &gic_r5 0xf9000000 0x10000>, 
			      <0x0 &psu_r5_1_atcm 0x0 0x10000>, 
			      <0x20000 &psu_r5_1_btcm 0x20000 0x10000>;
		#ranges-address-cells = <0x1>;
		#ranges-size-cells = <0x1>;
	};
	cpus_microblaze_0: cpus {
		compatible = "cpus,cluster";
		address-map = <0xf0000000 &amba 0xf0000000 0x10000000>, 
			      <0x0 &zynqmp_reset 0x0 0x0>, 
			      <0xFFFC0000 &psu_ocm_ram_0_memory 0xFFFC0000 0x40000>, 
			      <0xff330000 &ipi3 0xff330000 0x1000>, 
			      <0xff331000 &ipi4 0xff331000 0x1000>, 
			      <0xff332000 &ipi5 0xff332000 0x1000>, 
			      <0xff333000 &ipi6 0xff333000 0x1000>, 
			      <0x0 &psu_ddr_0_memory 0x0 0x7FF00000>, 
			      <0x7FF00000 &psu_ddr_0_memory 0x7FF00000 0x100000>, 
			      <0x84a10000 &rx_mxfe_tpl_core_adc_tpl_core 0x84a10000 0x2000>, 
			      <0x84a60000 &axi_mxfe_rx_xcvr 0x84a60000 0x10000>, 
			      <0x84a90000 &axi_mxfe_rx_jesd_rx_axi 0x84a90000 0x4000>, 
			      <0x84b10000 &tx_mxfe_tpl_core_dac_tpl_core 0x84b10000 0x2000>, 
			      <0x84b60000 &axi_mxfe_tx_xcvr 0x84b60000 0x10000>, 
			      <0x84b90000 &axi_mxfe_tx_jesd_tx_axi 0x84b90000 0x4000>, 
			      <0x85000000 &axi_sysid_0 0x85000000 0x10000>, 
			      <0x9c420000 &axi_mxfe_rx_dma 0x9c420000 0x1000>, 
			      <0x9c430000 &axi_mxfe_tx_dma 0x9c430000 0x1000>, 
			      <0x9c440000 &mxfe_tx_data_offload_i_data_offload 0x9c440000 0x10000>, 
			      <0x9c450000 &mxfe_rx_data_offload_i_data_offload 0x9c450000 0x10000>, 
			      <0xffa80000 &lpd_dma_chan1 0xffa80000 0x10000>, 
			      <0xffa90000 &lpd_dma_chan2 0xffa90000 0x10000>, 
			      <0xffaa0000 &lpd_dma_chan3 0xffaa0000 0x10000>, 
			      <0xffab0000 &lpd_dma_chan4 0xffab0000 0x10000>, 
			      <0xffac0000 &lpd_dma_chan5 0xffac0000 0x10000>, 
			      <0xffad0000 &lpd_dma_chan6 0xffad0000 0x10000>, 
			      <0xffae0000 &lpd_dma_chan7 0xffae0000 0x10000>, 
			      <0xffaf0000 &lpd_dma_chan8 0xffaf0000 0x10000>, 
			      <0xfd360000 &psu_afi_0 0xfd360000 0x10000>, 
			      <0xfd370000 &psu_afi_1 0xfd370000 0x10000>, 
			      <0xfd380000 &psu_afi_2 0xfd380000 0x10000>, 
			      <0xfd390000 &psu_afi_3 0xfd390000 0x10000>, 
			      <0xfd3a0000 &psu_afi_4 0xfd3a0000 0x10000>, 
			      <0xfd3b0000 &psu_afi_5 0xfd3b0000 0x10000>, 
			      <0xff9b0000 &psu_afi_6 0xff9b0000 0x10000>, 
			      <0xffa50000 &xilinx_ams 0xffa50000 0x10000>, 
			      <0xfd0b0000 &perf_monitor_ddr 0xfd0b0000 0x10000>, 
			      <0xffa00000 &perf_monitor_ocm 0xffa00000 0x10000>, 
			      <0xffa10000 &perf_monitor_lpd 0xffa10000 0x10000>, 
			      <0xfd490000 &perf_monitor_cci 0xfd490000 0x10000>, 
			      <0xfd5c0000 &psu_apu 0xfd5c0000 0x10000>, 
			      <0xff070000 &can1 0xff070000 0x10000>, 
			      <0xfd6e0000 &psu_cci_gpv 0xfd6e0000 0x10000>, 
			      <0xfd5e0000 &psu_cci_reg 0xfd5e0000 0x10000>, 
			      <0xfd1a0000 &psu_crf_apb 0xfd1a0000 0x140000>, 
			      <0xff5e0000 &psu_crl_apb 0xff5e0000 0x280000>, 
			      <0xffca0000 &psu_csu_0 0xffca0000 0x10000>, 
			      <0xffc80000 &csudma_0 0xffc80000 0x20000>, 
			      <0xff380000 &psu_ctrl_ipi 0xff380000 0x80000>, 
			      <0xfd080000 &psu_ddr_phy 0xfd080000 0x10000>, 
			      <0xfd090000 &psu_ddr_qos_ctrl 0xfd090000 0x10000>, 
			      <0xfd000000 &psu_ddr_xmpu0_cfg 0xfd000000 0x10000>, 
			      <0xfd010000 &psu_ddr_xmpu1_cfg 0xfd010000 0x10000>, 
			      <0xfd020000 &psu_ddr_xmpu2_cfg 0xfd020000 0x10000>, 
			      <0xfd030000 &psu_ddr_xmpu3_cfg 0xfd030000 0x10000>, 
			      <0xfd040000 &psu_ddr_xmpu4_cfg 0xfd040000 0x10000>, 
			      <0xfd050000 &psu_ddr_xmpu5_cfg 0xfd050000 0x10000>, 
			      <0xfd070000 &mc 0xfd070000 0x1000>, 
			      <0xfd4a0000 &zynqmp_dpsub 0xfd4a0000 0x10000>, 
			      <0xfd4c0000 &zynqmp_dpdma 0xfd4c0000 0x10000>, 
			      <0xffcc0000 &psu_efuse 0xffcc0000 0x10000>, 
			      <0xff0e0000 &gem3 0xff0e0000 0x10000>, 
			      <0xfd700000 &psu_fpd_gpv 0xfd700000 0x100000>, 
			      <0xfd610000 &psu_fpd_slcr 0xfd610000 0x80000>, 
			      <0xfd690000 &psu_fpd_slcr_secure 0xfd690000 0x40000>, 
			      <0xfd5d0000 &psu_fpd_xmpu_cfg 0xfd5d0000 0x10000>, 
			      <0xfd4f0000 &psu_fpd_xmpu_sink 0xfd4f0000 0x10000>, 
			      <0xfd500000 &fpd_dma_chan1 0xfd500000 0x10000>, 
			      <0xfd510000 &fpd_dma_chan2 0xfd510000 0x10000>, 
			      <0xfd520000 &fpd_dma_chan3 0xfd520000 0x10000>, 
			      <0xfd530000 &fpd_dma_chan4 0xfd530000 0x10000>, 
			      <0xfd540000 &fpd_dma_chan5 0xfd540000 0x10000>, 
			      <0xfd550000 &fpd_dma_chan6 0xfd550000 0x10000>, 
			      <0xfd560000 &fpd_dma_chan7 0xfd560000 0x10000>, 
			      <0xfd570000 &fpd_dma_chan8 0xfd570000 0x10000>, 
			      <0xff0a0000 &gpio 0xff0a0000 0x10000>, 
			      <0xfd4b0000 &gpu 0xfd4b0000 0x10000>, 
			      <0xff020000 &i2c0 0xff020000 0x10000>, 
			      <0xff030000 &i2c1 0xff030000 0x10000>, 
			      <0xff250000 &psu_iou_scntr 0xff250000 0x10000>, 
			      <0xff260000 &psu_iou_scntrs 0xff260000 0x10000>, 
			      <0xff240000 &psu_iousecure_slcr 0xff240000 0x10000>, 
			      <0xff180000 &psu_iouslcr_0 0xff180000 0xc0000>, 
			      <0xff410000 &psu_lpd_slcr 0xff410000 0xa0000>, 
			      <0xff4b0000 &psu_lpd_slcr_secure 0xff4b0000 0x30000>, 
			      <0xff980000 &lpd_xppu 0xff980000 0x10000>, 
			      <0xff9c0000 &psu_lpd_xppu_sink 0xff9c0000 0x10000>, 
			      <0xffcf0000 &psu_mbistjtag 0xffcf0000 0x10000>, 
			      <0xff990000 &psu_message_buffers 0xff990000 0x10000>, 
			      <0xff960000 &ocm 0xff960000 0x10000>, 
			      <0xffa70000 &psu_ocm_xmpu_cfg 0xffa70000 0x10000>, 
			      <0xfd0e0000 &pcie 0xfd0e0000 0x10000>, 
			      <0xfd480000 &psu_pcie_attrib_0 0xfd480000 0x10000>, 
			      <0xfd0f0000 &psu_pcie_dma 0xfd0f0000 0x10000>, 
			      <0xe0000000 &psu_pcie_low 0xe0000000 0x10000000>, 
			      <0xffd80000 &psu_pmu_global_0 0xffd80000 0x40000>, 
			      <0xff0f0000 &qspi 0xff0f0000 0x10000>, 
			      <0xc0000000 &psu_qspi_linear_0_memory 0xc0000000 0x20000000>, 
			      <0xffe00000 &psu_r5_0_atcm_global 0xffe00000 0x10000>, 
			      <0xffe20000 &psu_r5_0_btcm_global 0xffe20000 0x10000>, 
			      <0xffe90000 &psu_r5_1_atcm_global 0xffe90000 0x10000>, 
			      <0xffeb0000 &psu_r5_1_btcm_global 0xffeb0000 0x10000>, 
			      <0xffe00000 &psu_r5_tcm_ram_global 0xffe00000 0x40000>, 
			      <0xff9a0000 &psu_rpu 0xff9a0000 0x10000>, 
			      <0xffce0000 &psu_rsa 0xffce0000 0x10000>, 
			      <0xffa60000 &rtc 0xffa60000 0x10000>, 
			      <0xfd0c0000 &sata 0xfd0c0000 0x10000>, 
			      <0xff170000 &sdhci1 0xff170000 0x10000>, 
			      <0xfd400000 &psgtr 0xfd400000 0x80000>, 
			      <0xfd3d0000 &psu_siou 0xfd3d0000 0x10000>, 
			      <0xfd800000 &smmu 0xfd800000 0x800000>, 
			      <0xfd5f0000 &psu_smmu_reg 0xfd5f0000 0x10000>, 
			      <0xff040000 &spi0 0xff040000 0x10000>, 
			      <0xff050000 &spi1 0xff050000 0x10000>, 
			      <0xff110000 &ttc0 0xff110000 0x10000>, 
			      <0xff120000 &ttc1 0xff120000 0x10000>, 
			      <0xff130000 &ttc2 0xff130000 0x10000>, 
			      <0xff140000 &ttc3 0xff140000 0x10000>, 
			      <0xff000000 &uart0 0xff000000 0x10000>, 
			      <0xff010000 &uart1 0xff010000 0x10000>, 
			      <0xff9d0000 &usb0 0xff9d0000 0x10000>, 
			      <0xfe200000 &dwc3_0 0xfe200000 0x100000>, 
			      <0xff150000 &lpd_watchdog 0xff150000 0x10000>, 
			      <0xfd4d0000 &watchdog0 0xfd4d0000 0x10000>, 
			      <0xffcb0000 &csuwdt_0 0xffcb0000 0x10000>, 
			      <0xffcd0000 &psu_bbram_0 0xffcd0000 0x10000>, 
			      <0xffd40000 &psu_pmu_iomodule 0xffd40000 0x20000>, 
			      <0xffdc0000 &psu_pmu_ram 0xffdc0000 0x20000>;
		#ranges-address-cells = <0x1>;
		#ranges-size-cells = <0x1>;
	};
};

	&spi1 {
		status = "okay";
		#address-cells = <1>;
		#size-cells = <0>;
		hmc7044: hmc7044@0 {
			compatible = "adi,hmc7044";
			#address-cells = <1>;
			#size-cells = <0>;
			#clock-cells = <1>;
			#jesd204-cells = <2>;
			jesd204-device;
			reg = <0>;
			adi,gpi-controls = <0x00 0x00 0x00 0x00>;
			adi,gpo-controls = <0x37 0x33 0x00 0x00>;
			spi-max-frequency = <1000000>;
			adi,pll1-clkin-frequencies = <122880000 30720000 0 0>;
			adi,pll1-ref-prio-ctrl = <0xE1>;
			adi,pll1-ref-autorevert-enable;
			adi,pll1-loop-bandwidth-hz = <200>;
			adi,pll1-charge-pump-current-ua = <720>;
			adi,pfd1-maximum-limit-frequency-hz = <1000000>;
			adi,vcxo-frequency = <122880000>;
			adi,pll2-output-frequency = <3000000000>;
			adi,sysref-timer-divider = <1024>;
			adi,pulse-generator-mode = <0>;
			jesd204-sysref-provider;
			adi,jesd204-max-sysref-frequency-hz = <2000000>;
			adi,clkin0-buffer-mode = <0x07>;
			adi,clkin1-buffer-mode = <0x07>;
			adi,oscin-buffer-mode = <0x15>;
			clock-output-names = "hmc7044_out0", "hmc7044_out1", "hmc7044_out2", "hmc7044_out3", "hmc7044_out4", "hmc7044_out5", "hmc7044_out6", "hmc7044_out7", "hmc7044_out8", "hmc7044_out9", "hmc7044_out10", "hmc7044_out11", "hmc7044_out12", "hmc7044_out13";
			hmc7044_c0: channel@0 {
				reg = <0>;
				adi,extended-name = "CORE_CLK_RX";
				adi,divider = <12>;
				adi,driver-mode = <2>;
			};
			hmc7044_c2: channel@2 {
				reg = <2>;
				adi,extended-name = "DEV_REFCLK";
				adi,divider = <12>;
				adi,driver-mode = <2>;
			};
			hmc7044_c3: channel@3 {
				reg = <3>;
				adi,extended-name = "DEV_SYSREF";
				adi,divider = <1536>;
				adi,driver-mode = <2>;
				adi,jesd204-sysref-chan;
			};
			hmc7044_c6: channel@6 {
				reg = <6>;
				adi,extended-name = "CORE_CLK_TX";
				adi,divider = <12>;
				adi,driver-mode = <2>;
			};
			hmc7044_c8: channel@8 {
				reg = <8>;
				adi,extended-name = "FPGA_REFCLK1";
				adi,divider = <6>;
				adi,driver-mode = <2>;
			};
			hmc7044_c10: channel@10 {
				reg = <10>;
				adi,extended-name = "CORE_CLK_RX_ALT";
				adi,divider = <12>;
				adi,driver-mode = <2>;
			};
			hmc7044_c12: channel@12 {
				reg = <12>;
				adi,extended-name = "FPGA_REFCLK2";
				adi,divider = <6>;
				adi,driver-mode = <2>;
			};
			hmc7044_c13: channel@13 {
				reg = <13>;
				adi,extended-name = "FPGA_SYSREF";
				adi,divider = <1536>;
				adi,driver-mode = <2>;
				adi,jesd204-sysref-chan;
			};
		};
	};
	&spi0 {
		status = "okay";
		#address-cells = <1>;
		#size-cells = <0>;
		trx0_ad9081: ad9081@0 {
			compatible = "adi,ad9081";
			#clock-cells = <1>;
			clock-output-names = "rx_sampl_clk", "tx_sampl_clk";
			#jesd204-cells = <2>;
			jesd204-top-device = <0>;
			jesd204-device;
			reg = <0>;
			reset-gpios = <&gpio 133 0>;
			sysref-req-gpios = <&gpio 121 0>;
			rx2-enable-gpios = <&gpio 135 0>;
			rx1-enable-gpios = <&gpio 134 0>;
			tx2-enable-gpios = <&gpio 137 0>;
			tx1-enable-gpios = <&gpio 136 0>;
			clocks = <&hmc7044 2>;
			clock-names = "dev_clk";
			jesd204-link-ids = <2 0>;
			jesd204-inputs = <&rx_mxfe_tpl_core_adc_tpl_core 0 2>, <&tx_mxfe_tpl_core_dac_tpl_core 0 0>;
			spi-max-frequency = <5000000>;
			adi,tx-dacs {
				#size-cells = <0>;
				#address-cells = <1>;
				adi,dac-frequency-hz = /bits/ 64 <12000000000>;
				adi,main-data-paths {
					#address-cells = <1>;
					#size-cells = <0>;
					adi,interpolation = <8>;
					dac@0 { reg = <0>; adi,crossbar-select = <0x28>; adi,nco-frequency-shift-hz = /bits/ 64 <0>; };
					dac@1 { reg = <1>; adi,crossbar-select = <0x29>; adi,nco-frequency-shift-hz = /bits/ 64 <0>; };
					dac@2 { reg = <2>; adi,crossbar-select = <0x2a>; adi,nco-frequency-shift-hz = /bits/ 64 <0>; };
					dac@3 { reg = <3>; adi,crossbar-select = <0x2b>; adi,nco-frequency-shift-hz = /bits/ 64 <0>; };
				};
				adi,channelizer-paths {
					#address-cells = <1>;
					#size-cells = <0>;
					adi,interpolation = <6>;
					ad9081_tx_fddc_chan0: channel@0 { reg = <0>; adi,gain = <2048>; adi,nco-frequency-shift-hz = /bits/ 64 <0>; };
					ad9081_tx_fddc_chan1: channel@1 { reg = <1>; adi,gain = <2048>; adi,nco-frequency-shift-hz = /bits/ 64 <0>; };
					ad9081_tx_fddc_chan2: channel@2 { reg = <2>; adi,gain = <2048>; adi,nco-frequency-shift-hz = /bits/ 64 <0>; };
					ad9081_tx_fddc_chan3: channel@3 { reg = <3>; adi,gain = <2048>; adi,nco-frequency-shift-hz = /bits/ 64 <0>; };
					ad9081_tx_fddc_chan4: channel@4 { reg = <4>; adi,gain = <2048>; adi,nco-frequency-shift-hz = /bits/ 64 <0>; };
					ad9081_tx_fddc_chan5: channel@5 { reg = <5>; adi,gain = <2048>; adi,nco-frequency-shift-hz = /bits/ 64 <0>; };
					ad9081_tx_fddc_chan6: channel@6 { reg = <6>; adi,gain = <2048>; adi,nco-frequency-shift-hz = /bits/ 64 <0>; };
					ad9081_tx_fddc_chan7: channel@7 { reg = <7>; adi,gain = <2048>; adi,nco-frequency-shift-hz = /bits/ 64 <0>; };
				};
				adi,jesd-links {
					#size-cells = <0>;
					#address-cells = <1>;
					link@0 {
						reg = <0>;
						adi,converter-select = <&ad9081_tx_fddc_chan0 0>, <&ad9081_tx_fddc_chan0 1>, <&ad9081_tx_fddc_chan1 0>, <&ad9081_tx_fddc_chan1 1>, <&ad9081_tx_fddc_chan2 0>, <&ad9081_tx_fddc_chan2 1>, <&ad9081_tx_fddc_chan3 0>, <&ad9081_tx_fddc_chan3 1>;
						adi,logical-lane-mapping = /bits/ 8 <0 2 7 7 1 7 7 3>;
						adi,link-mode = <9>;
						adi,subclass = <1>;
						adi,version = <1>;
						adi,dual-link = <0>;
						adi,converters-per-device = <8>;
						adi,octets-per-frame = <4>;
						adi,frames-per-multiframe = <32>;
						adi,converter-resolution = <16>;
						adi,bits-per-sample = <16>;
						adi,control-bits-per-sample = <0>;
						adi,lanes-per-device = <4>;
						adi,samples-per-converter-per-frame = <1>;
						adi,high-density = <0>;
						adi,tpl-phase-adjust = <3>;
					};
				};
			};
			adi,rx-adcs {
				#size-cells = <0>;
				#address-cells = <1>;
				adi,adc-frequency-hz = /bits/ 64 <4000000000>;
				adi,main-data-paths {
					#address-cells = <1>;
					#size-cells = <0>;
					adc@0 { reg = <0>; adi,decimation = <4>; adi,nco-frequency-shift-hz = /bits/ 64 <0>; adi,nco-mixer-mode = <0>; };
					adc@1 { reg = <1>; adi,decimation = <4>; adi,nco-frequency-shift-hz = /bits/ 64 <0>; adi,nco-mixer-mode = <0>; };
					adc@2 { reg = <2>; adi,decimation = <4>; adi,nco-frequency-shift-hz = /bits/ 64 <0>; adi,nco-mixer-mode = <0>; };
					adc@3 { reg = <3>; adi,decimation = <4>; adi,nco-frequency-shift-hz = /bits/ 64 <0>; adi,nco-mixer-mode = <0>; };
				};
				adi,channelizer-paths {
					#address-cells = <1>;
					#size-cells = <0>;
					ad9081_rx_fddc_chan0: channel@0 { reg = <0>; adi,decimation = <4>; adi,gain = <2048>; adi,nco-frequency-shift-hz = /bits/ 64 <0>; };
					ad9081_rx_fddc_chan1: channel@1 { reg = <1>; adi,decimation = <4>; adi,gain = <2048>; adi,nco-frequency-shift-hz = /bits/ 64 <0>; };
					ad9081_rx_fddc_chan2: channel@2 { reg = <2>; adi,decimation = <4>; adi,gain = <2048>; adi,nco-frequency-shift-hz = /bits/ 64 <0>; };
					ad9081_rx_fddc_chan3: channel@3 { reg = <3>; adi,decimation = <4>; adi,gain = <2048>; adi,nco-frequency-shift-hz = /bits/ 64 <0>; };
					ad9081_rx_fddc_chan4: channel@4 { reg = <4>; adi,decimation = <4>; adi,gain = <2048>; adi,nco-frequency-shift-hz = /bits/ 64 <0>; };
					ad9081_rx_fddc_chan5: channel@5 { reg = <5>; adi,decimation = <4>; adi,gain = <2048>; adi,nco-frequency-shift-hz = /bits/ 64 <0>; };
					ad9081_rx_fddc_chan6: channel@6 { reg = <6>; adi,decimation = <4>; adi,gain = <2048>; adi,nco-frequency-shift-hz = /bits/ 64 <0>; };
					ad9081_rx_fddc_chan7: channel@7 { reg = <7>; adi,decimation = <4>; adi,gain = <2048>; adi,nco-frequency-shift-hz = /bits/ 64 <0>; };
				};
				adi,jesd-links {
					#size-cells = <0>;
					#address-cells = <1>;
					link@0 {
						reg = <0>;
						adi,converter-select = <&ad9081_rx_fddc_chan0 0>, <&ad9081_rx_fddc_chan0 1>, <&ad9081_rx_fddc_chan1 0>, <&ad9081_rx_fddc_chan1 1>, <&ad9081_rx_fddc_chan2 0>, <&ad9081_rx_fddc_chan2 1>, <&ad9081_rx_fddc_chan3 0>, <&ad9081_rx_fddc_chan3 1>;
						adi,logical-lane-mapping = /bits/ 8 <2 0 7 7 7 7 3 1>;
						adi,link-mode = <10>;
						adi,subclass = <1>;
						adi,version = <1>;
						adi,dual-link = <0>;
						adi,converters-per-device = <8>;
						adi,octets-per-frame = <4>;
						adi,frames-per-multiframe = <32>;
						adi,converter-resolution = <16>;
						adi,bits-per-sample = <16>;
						adi,control-bits-per-sample = <0>;
						adi,lanes-per-device = <4>;
						adi,samples-per-converter-per-frame = <1>;
						adi,high-density = <0>;
					};
				};
			};
		};
	};
	&axi_mxfe_rx_dma {
		/delete-property/ compatible;
		compatible = "adi,axi-dmac-1.00.a";
		#dma-cells = <1>;
		#clock-cells = <0>;
	};
	&rx_mxfe_tpl_core_adc_tpl_core {
		/delete-property/ compatible;
		/delete-property/ clocks;
		/delete-property/ clock-names;
		#jesd204-cells = <2>;
		jesd204-device;
		dmas = <&axi_mxfe_rx_dma 0>;
		dma-names = "rx";
		spibus-connected = <&trx0_ad9081>;
		jesd204-inputs = <&axi_mxfe_rx_jesd_rx_axi 0 2>;
		compatible = "adi,axi-ad9081-rx-1.0";
	};
	&axi_mxfe_rx_xcvr {
		/delete-property/ compatible;
		/delete-property/ clocks;
		/delete-property/ clock-names;
		/delete-property/ #clock-cells;
		/delete-property/ clock-output-names;
		/delete-property/ adi,sys-clk-select;
		/delete-property/ adi,out-clk-select;
		compatible = "adi,axi-adxcvr-1.0";
		#clock-cells = <1>;
		#jesd204-cells = <2>;
		jesd204-device;
		clocks = <&hmc7044 12>;
		clock-names = "conv";
		clock-output-names = "rx_gt_clk", "rx_out_clk";
		jesd204-inputs = <&hmc7044 0 2>;
		adi,sys-clk-select = <3>;
		adi,out-clk-select = <4>;
		adi,use-lpm-enable;
	};
	&axi_mxfe_tx_dma {
		/delete-property/ compatible;
		compatible = "adi,axi-dmac-1.00.a";
		#dma-cells = <1>;
		#clock-cells = <0>;
	};
	&tx_mxfe_tpl_core_dac_tpl_core {
		/delete-property/ compatible;
		/delete-property/ clocks;
		/delete-property/ clock-names;
		#jesd204-cells = <2>;
		jesd204-device;
		dmas = <&axi_mxfe_tx_dma 0>;
		dma-names = "tx";
		clocks = <&trx0_ad9081 1>;
		clock-names = "sampl_clk";
		spibus-connected = <&trx0_ad9081>;
		jesd204-inputs = <&axi_mxfe_tx_jesd_tx_axi 0 0>;
		compatible = "adi,axi-ad9081-tx-1.0";
	};
	&axi_mxfe_tx_xcvr {
		/delete-property/ compatible;
		/delete-property/ clocks;
		/delete-property/ clock-names;
		/delete-property/ #clock-cells;
		/delete-property/ clock-output-names;
		/delete-property/ adi,sys-clk-select;
		/delete-property/ adi,out-clk-select;
		compatible = "adi,axi-adxcvr-1.0";
		#clock-cells = <1>;
		#jesd204-cells = <2>;
		jesd204-device;
		clocks = <&hmc7044 12>;
		clock-names = "conv";
		clock-output-names = "tx_gt_clk", "tx_out_clk";
		jesd204-inputs = <&hmc7044 0 0>;
		adi,sys-clk-select = <3>;
		adi,out-clk-select = <4>;
	};
	&axi_mxfe_rx_jesd_rx_axi {
		/delete-property/ compatible;
		/delete-property/ clocks;
		/delete-property/ clock-names;
		/delete-property/ #clock-cells;
		/delete-property/ adi,octets-per-frame;
		/delete-property/ adi,frames-per-multiframe;
		#clock-cells = <0>;
		#jesd204-cells = <2>;
		jesd204-device;
		clocks = <&zynqmp_clk 71>, <&hmc7044 10>, <&axi_mxfe_rx_xcvr 0>;
		clock-names = "s_axi_aclk", "device_clk", "lane_clk";
		jesd204-inputs = <&axi_mxfe_rx_xcvr 0 2>;
		compatible = "adi,axi-jesd204-rx-1.0";
		adi,octets-per-frame = <4>;
		adi,frames-per-multiframe = <32>;
	};
	&axi_mxfe_tx_jesd_tx_axi {
		/delete-property/ compatible;
		/delete-property/ clocks;
		/delete-property/ clock-names;
		/delete-property/ #clock-cells;
		/delete-property/ adi,octets-per-frame;
		/delete-property/ adi,frames-per-multiframe;
		#clock-cells = <0>;
		#jesd204-cells = <2>;
		jesd204-device;
		clocks = <&zynqmp_clk 71>, <&hmc7044 6>, <&axi_mxfe_tx_xcvr 0>;
		clock-names = "s_axi_aclk", "device_clk", "lane_clk";
		jesd204-inputs = <&axi_mxfe_tx_xcvr 0 0>;
		compatible = "adi,axi-jesd204-tx-1.0";
		adi,octets-per-frame = <4>;
		adi,frames-per-multiframe = <32>;
	};
